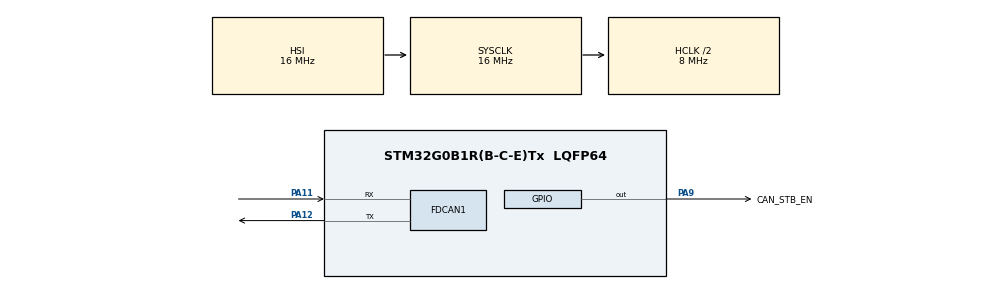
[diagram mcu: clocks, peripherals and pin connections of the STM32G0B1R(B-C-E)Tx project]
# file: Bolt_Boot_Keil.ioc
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FDCAN1.CalculateBaudRateNominal=1000000
FDCAN1.CalculateTimeBitNominal=1000
FDCAN1.CalculateTimeQuantumNominal=62.5
FDCAN1.DataSyncJumpWidth=4
FDCAN1.DataTimeSeg1=12
FDCAN1.DataTimeSeg2=3
FDCAN1.ExtFiltersNbr=2
FDCAN1.NominalPrescaler=1
FDCAN1.NominalSyncJumpWidth=4
FDCAN1.NominalTimeSeg1=12
FDCAN1.NominalTimeSeg2=3
Mcu.Family=STM32G0
Mcu.Name=STM32G0B1R(B-C-E)Tx
Mcu.Package=LQFP64
NVIC.TIM16_FDCAN_IT0_IRQn=true\:0\:0\:false\:false\:true\:true\:true\:true
NVIC.TIM17_FDCAN_IT1_IRQn=true\:0\:0\:false\:false\:true\:true\:true\:true
PA11\ [PA9].Mode=FDCAN_Activate
PA11\ [PA9].Signal=FDCAN1_RX
PA12\ [PA10].Mode=FDCAN_Activate
PA12\ [PA10].Signal=FDCAN1_TX
PA13.Mode=Serial_Wire
PA13.Signal=SYS_SWDIO
PA14-BOOT0.Mode=Serial_Wire
PA14-BOOT0.Signal=SYS_SWCLK
PA9.GPIO_Label=CAN_STB_EN
PA9.Signal=GPIO_Output
ProjectManager.HeapSize=0x400
ProjectManager.StackSize=0x400
ProjectManager.TargetToolchain=MDK-ARM V5.32
RCC.AHBCLKDivider=RCC_SYSCLK_DIV2
RCC.AHBFreq_Value=8000000
RCC.CortexFreq_Value=8000000
RCC.EXTERNAL_CLOCK_VALUE=48000
RCC.FDCANCLockSelection=RCC_FDCANCLKSOURCE_PLL
RCC.HCLKFreq_Value=8000000
RCC.HSE_VALUE=8000000
RCC.HSI48_VALUE=48000000
RCC.HSI_VALUE=16000000
RCC.LSE_VALUE=32768
RCC.PLLQ=RCC_PLLQ_DIV8
RCC.SYSCLKFreq_VALUE=16000000
RCC.USBFreq_Value=48000000
RCC.VCOOutputFreq_Value=128000000
VP_SYS_VS_DBSignals.Mode=DisableDeadBatterySignals
board=custom

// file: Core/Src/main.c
/* USER CODE BEGIN Header */
/**
  ******************************************************************************
  * @file           : main.c
  * @brief          : Main program body
  ******************************************************************************
  * @attention
  *
  * Copyright (c) 2023 STMicroelectronics.
  * All rights reserved.
  *
  * This software is licensed under terms that can be found in the LICENSE file
  * in the root directory of this software component.
  * If no LICENSE file comes with this software, it is provided AS-IS.
  *
  ******************************************************************************
  */
/* USER CODE END Header */
#include "main.h"

/* USER CODE BEGIN Includes */
#include "can.h"
#include "comm_cir_handle.h"
#include "CAN_CircularBuf.h"
/* USER CODE END Includes */

FDCAN_HandleTypeDef hfdcan1;

void SystemClock_Config(void);
static void MX_GPIO_Init(void);
static void MX_FDCAN1_Init(void);

/* USER CODE BEGIN 0 */
u8 au8data[1];
/* USER CODE END 0 */

int main(void)
{

  /* MCU Configuration--------------------------------------------------------*/

  /* Reset of all peripherals, Initializes the Flash interface and the Systick. */
  HAL_Init();

  /* Configure the system clock */
  SystemClock_Config();

  /* Initialize all configured peripherals */
  MX_GPIO_Init();
  MX_FDCAN1_Init();
  /* USER CODE BEGIN 2 */
  can_circulbuf_init();
  /* USER CODE END 2 */

  /* Infinite loop */
  while (1)
  {
	CAN_DataDecode();
  }
}

void SystemClock_Config(void)
{
  RCC_OscInitTypeDef RCC_OscInitStruct = {0};
  RCC_ClkInitTypeDef RCC_ClkInitStruct = {0};

  /** Configure the main internal regulator output voltage
  */
  HAL_PWREx_ControlVoltageScaling(PWR_REGULATOR_VOLTAGE_SCALE1);

  /** Initializes the RCC Oscillators according to the specified parameters
  * in the RCC_OscInitTypeDef structure.
  */
  RCC_OscInitStruct.OscillatorType = RCC_OSCILLATORTYPE_HSI;
  RCC_OscInitStruct.HSIState = RCC_HSI_ON;
  RCC_OscInitStruct.HSIDiv = RCC_HSI_DIV1;
  RCC_OscInitStruct.HSICalibrationValue = RCC_HSICALIBRATION_DEFAULT;
  RCC_OscInitStruct.PLL.PLLState = RCC_PLL_ON;
  RCC_OscInitStruct.PLL.PLLSource = RCC_PLLSOURCE_HSI;
  RCC_OscInitStruct.PLL.PLLM = RCC_PLLM_DIV1;
  RCC_OscInitStruct.PLL.PLLN = 8;
  RCC_OscInitStruct.PLL.PLLP = RCC_PLLP_DIV2;
  RCC_OscInitStruct.PLL.PLLQ = RCC_PLLQ_DIV8;
  RCC_OscInitStruct.PLL.PLLR = RCC_PLLR_DIV2;
  if (HAL_RCC_OscConfig(&RCC_OscInitStruct) != HAL_OK)
  {
    Error_Handler();
  }

  /** Initializes the CPU, AHB and APB buses clocks
  */
  RCC_ClkInitStruct.ClockType = RCC_CLOCKTYPE_HCLK|RCC_CLOCKTYPE_SYSCLK
                              |RCC_CLOCKTYPE_PCLK1;
  RCC_ClkInitStruct.SYSCLKSource = RCC_SYSCLKSOURCE_HSI;
  RCC_ClkInitStruct.AHBCLKDivider = RCC_SYSCLK_DIV2;
  RCC_ClkInitStruct.APB1CLKDivider = RCC_HCLK_DIV1;

  if (HAL_RCC_ClockConfig(&RCC_ClkInitStruct, FLASH_LATENCY_0) != HAL_OK)
  {
    Error_Handler();
  }
}

static void MX_FDCAN1_Init(void)
{

  hfdcan1.Instance = FDCAN1;
  hfdcan1.Init.ClockDivider = FDCAN_CLOCK_DIV1;
  hfdcan1.Init.FrameFormat = FDCAN_FRAME_CLASSIC;
  hfdcan1.Init.Mode = FDCAN_MODE_NORMAL;
  hfdcan1.Init.AutoRetransmission = DISABLE;
  hfdcan1.Init.TransmitPause = DISABLE;
  hfdcan1.Init.ProtocolException = DISABLE;
  hfdcan1.Init.NominalPrescaler = 1;
  hfdcan1.Init.NominalSyncJumpWidth = 4;
  hfdcan1.Init.NominalTimeSeg1 = 12;
  hfdcan1.Init.NominalTimeSeg2 = 3;
  hfdcan1.Init.DataPrescaler = 1;
  hfdcan1.Init.DataSyncJumpWidth = 4;
  hfdcan1.Init.DataTimeSeg1 = 12;
  hfdcan1.Init.DataTimeSeg2 = 3;
  hfdcan1.Init.StdFiltersNbr = 0;
  hfdcan1.Init.ExtFiltersNbr = 2;
  hfdcan1.Init.TxFifoQueueMode = FDCAN_TX_FIFO_OPERATION;
  if (HAL_FDCAN_Init(&hfdcan1) != HAL_OK)
  {
    Error_Handler();
  }
  /* USER CODE BEGIN FDCAN1_Init 2 */
	HAL_FDCAN_ActivateNotification(&hfdcan1, FDCAN_IT_LIST_RX_FIFO0, 0);
	if (HAL_FDCAN_Start(&hfdcan1) != HAL_OK)
	{
		Error_Handler();
	}
  /* USER CODE END FDCAN1_Init 2 */

}

static void MX_GPIO_Init(void)
{
  GPIO_InitTypeDef GPIO_InitStruct = {0};

  /* GPIO Ports Clock Enable */
  __HAL_RCC_GPIOA_CLK_ENABLE();

  /*Configure GPIO pin Output Level */
  HAL_GPIO_WritePin(CAN_STB_EN_GPIO_Port, CAN_STB_EN_Pin, GPIO_PIN_RESET);

  /*Configure GPIO pin : CAN_STB_EN_Pin */
  GPIO_InitStruct.Pin = CAN_STB_EN_Pin;
  GPIO_InitStruct.Mode = GPIO_MODE_OUTPUT_PP;
  GPIO_InitStruct.Pull = GPIO_NOPULL;
  GPIO_InitStruct.Speed = GPIO_SPEED_FREQ_LOW;
  HAL_GPIO_Init(CAN_STB_EN_GPIO_Port, &GPIO_InitStruct);

}

/* USER CODE BEGIN 4 */
void FDCAN1_Init(void)
{
	MX_FDCAN1_Init();
}
/* USER CODE END 4 */

void Error_Handler(void)
{
  __disable_irq();
  while (1)
  {
  }
}
